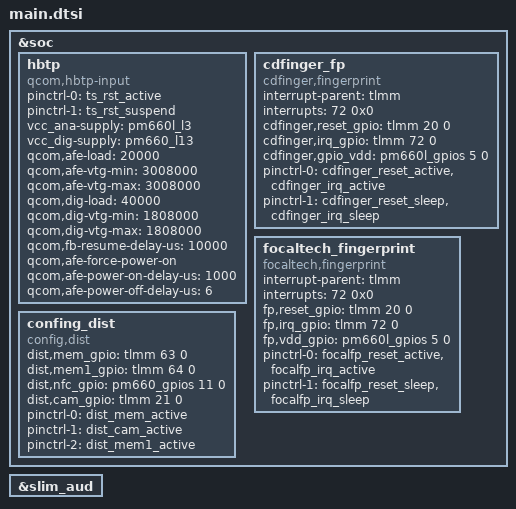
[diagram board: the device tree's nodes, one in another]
// SPDX-License-Identifier: GPL-2.0
// Copyright (C) 2021 Atom-X-Devs < https://www.github.com/Atom-X-Devs >

#include "asus-x01bd-camera.dtsi"
#include "asus-x01bd-i2c.dtsi"
#include "asus-x01bd-mdss.dtsi"
#include "asus-x01bd-pinctrl.dtsi"

// asus X00TD misc changes
&soc {
	hbtp {
		compatible = "qcom,hbtp-input";
		pinctrl-names = "pmx_ts_active", "pmx_ts_suspend";
		pinctrl-0 = <&ts_rst_active>;
		pinctrl-1 = <&ts_rst_suspend>;
		vcc_ana-supply = <&pm660l_l3>;
		vcc_dig-supply = <&pm660_l13>;
		qcom,afe-load = <20000>;
		qcom,afe-vtg-min = <3008000>;
		qcom,afe-vtg-max = <3008000>;
		qcom,dig-load = <40000>;
		qcom,dig-vtg-min = <1808000>;
		qcom,dig-vtg-max = <1808000>;
		qcom,fb-resume-delay-us = <10000>;
		qcom,afe-force-power-on;
		qcom,afe-power-on-delay-us = <1000>;
		qcom,afe-power-off-delay-us = <6>;
	};

	cdfinger_fp {
		compatible = "cdfinger,fingerprint";
		interrupt-parent = <&tlmm>;
		interrupts = <72 0x0>;
		cdfinger,reset_gpio = <&tlmm 20 0>;
		cdfinger,irq_gpio = <&tlmm 72 0>;
		cdfinger,gpio_vdd = <&pm660l_gpios 5 0>;

		pinctrl-names = "cdfinger_active",
				"cdfinger_sleep";
		pinctrl-0 = <&cdfinger_reset_active &cdfinger_irq_active>;
		pinctrl-1 = <&cdfinger_reset_sleep &cdfinger_irq_sleep>;
	};

	focaltech_fingerprint {
		compatible = "focaltech,fingerprint";
		interrupt-parent = <&tlmm>;
		interrupts = <72 0x0>;
		fp,reset_gpio   = <&tlmm 20 0>;
		fp,irq_gpio        = <&tlmm 72 0>;
		fp,vdd_gpio        = <&pm660l_gpios 5 0>;

		pinctrl-names = "focalfp_active",
				"focalfp_sleep";
		pinctrl-0 = <&focalfp_reset_active &focalfp_irq_active>;
		pinctrl-1 = <&focalfp_reset_sleep &focalfp_irq_sleep>;
	};

	confing_dist {
		compatible = "config,dist";
		dist,mem_gpio = <&tlmm 63 0>;
		dist,mem1_gpio = <&tlmm 64 0>;
		dist,nfc_gpio = <&pm660_gpios 11 0>;
		dist,cam_gpio = <&tlmm 21 0>;

		pinctrl-names = "dist_mem_active",
				"dist_cam_active",
				"dist_mem1_active";
		pinctrl-0 = <&dist_mem_active>;
		pinctrl-1 = <&dist_cam_active>;
		pinctrl-2 = <&dist_mem1_active>;
	};

	/delete-node/sound-tavil;
};

&slim_aud {
	/delete-node/wcd934x_cdc;
};
